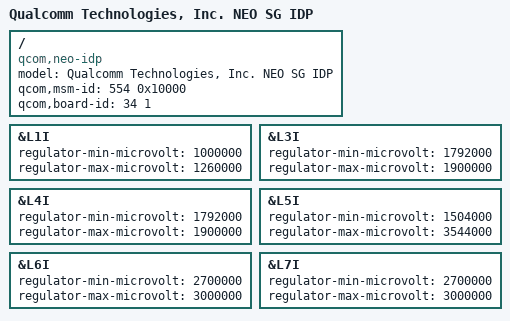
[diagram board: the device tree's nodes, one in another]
/dts-v1/;
/plugin/;

#include "neo-sg-idp.dtsi"
#include "neo-pm8010.dtsi"

/ {
	model = "Qualcomm Technologies, Inc. NEO SG IDP";
	compatible = "qcom,neo-idp", "qcom,neo", "qcom,idp";
	qcom,msm-id = <554 0x10000>;
	qcom,board-id = <34 1>;
};

&L1I {
	regulator-min-microvolt = <1000000>;
	regulator-max-microvolt = <1260000>;
};

&L3I {
	regulator-min-microvolt = <1792000>;
	regulator-max-microvolt = <1900000>;
};

&L4I {
	regulator-min-microvolt = <1792000>;
	regulator-max-microvolt = <1900000>;
};

&L5I {
	regulator-min-microvolt = <1504000>;
	regulator-max-microvolt = <3544000>;
};

&L6I {
	regulator-min-microvolt = <2700000>;
	regulator-max-microvolt = <3000000>;
};

&L7I {
	regulator-min-microvolt = <2700000>;
	regulator-max-microvolt = <3000000>;
};
